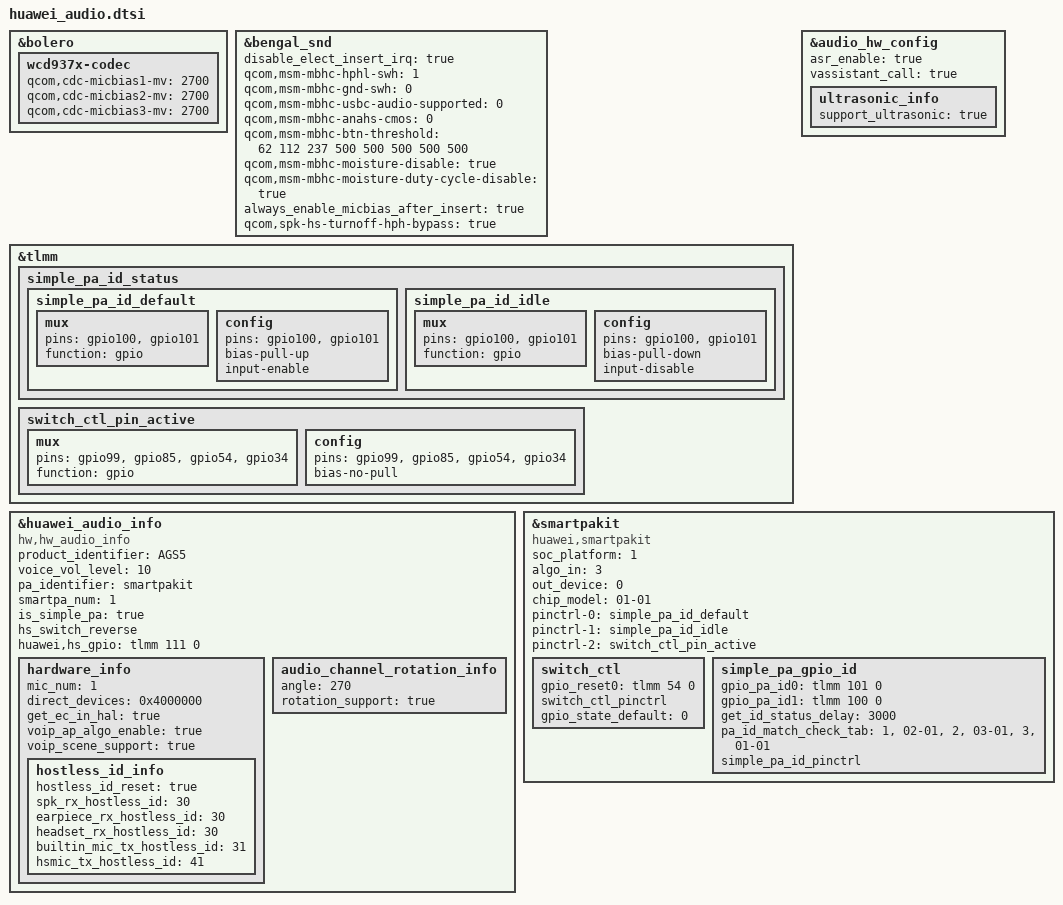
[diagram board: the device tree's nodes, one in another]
&bolero {
	wcd937x-codec {
		qcom,cdc-micbias1-mv = <2700>;
		qcom,cdc-micbias2-mv = <2700>;
		qcom,cdc-micbias3-mv = <2700>;
	};
};

&bengal_snd {
	disable_elect_insert_irq = "true";
	qcom,msm-mbhc-hphl-swh = <1>;
	qcom,msm-mbhc-gnd-swh = <0>;
	qcom,msm-mbhc-usbc-audio-supported = <0>;
	qcom,msm-mbhc-anahs-cmos = <0>;
	qcom,msm-mbhc-btn-threshold = /bits/ 16 <62 112 237 500 500 500 500 500>;
	qcom,msm-mbhc-moisture-disable = "true";
	qcom,msm-mbhc-moisture-duty-cycle-disable = "true";
	always_enable_micbias_after_insert = "true";
	qcom,spk-hs-turnoff-hph-bypass = "true";
};

&tlmm {
	simple_pa_id_status: simple_pa_id_status {
		simple_pa_id_default: simple_pa_id_default {
			mux {
				pins = "gpio100", "gpio101";
				function = "gpio";
			};

			config {
				pins = "gpio100", "gpio101";
				bias-pull-up;
				input-enable;
			};
		};

		simple_pa_id_idle: simple_pa_id_idle {
			mux {
				pins = "gpio100", "gpio101";
				function = "gpio";
			};

			config {
				pins = "gpio100", "gpio101";
				bias-pull-down;
				input-disable;
			};
		};
	};

	switch_ctl_pin_active: switch_ctl_pin_active {
		mux {
			pins = "gpio99", "gpio85", "gpio54", "gpio34";
			function = "gpio";
		};

		config {
			pins = "gpio99", "gpio85", "gpio54", "gpio34";
			bias-no-pull;
		};
	};
};

&huawei_audio_info {
	compatible = "hw,hw_audio_info";
	product_identifier = "AGS5";
	voice_vol_level = "10";
	pa_identifier = "smartpakit";
	smartpa_num = <1>;
	status = "ok";
	is_simple_pa = "true";
	hs_switch_reverse;
	huawei,hs_gpio = <&tlmm 111 0>;
	hardware_info {
		mic_num = "1";
		direct_devices = "0x4000000";
		get_ec_in_hal = "true";
		voip_ap_algo_enable = "true";
		voip_scene_support = "true";
		status = "ok";
		hostless_id_info {
			hostless_id_reset = "true";
			spk_rx_hostless_id = "30";
			earpiece_rx_hostless_id = "30";
			headset_rx_hostless_id = "30";
			builtin_mic_tx_hostless_id = "31";
			hsmic_tx_hostless_id = "41";
		};
	};

	audio_channel_rotation_info {
		angle="270";
		rotation_support= "true";
	};
};

&audio_hw_config {
	asr_enable = "true";
	vassistant_call = "true";
	ultrasonic_info {
		support_ultrasonic = "true";
	};
};

&smartpakit {
	compatible = "huawei,smartpakit";
	/* 0 hisi, 1 qcom */
	soc_platform = <1>;
	/* algo running on: 0 codec_dsp, 1 soc_dsp, 2 smartpa_dsp, 3 simple pa(not smpartpa), 4 simple pa(with i2c) */
	algo_in = <3>;
	/* algo_in params need match out_device for smartpa.
	 * Now, up to only support eight pa, so out_device = <0 0 0 0 0 0 0 0>;
	 * 1. This array is arranged in the following order:
	 *    <0 1 2 3>
	 *    <pril prir secl secr>
	 * 2. This array element value is 0 or 1:
	 *    smartpa: 0 speaker, 1 receiver
	 *    simple pa: out_device not applicable, only set 0 to indicate pa_num
	 * 3. The length of this array is variable, for example:
	 *    single pa: out_device = <0>;
	 *    two pa: out_device = <0 0>;
	 *    four pa: out_device = <1 1 0 0>;
	 *    eight pa: out_device = <0 0 0 0 0 0 0 0>; */
	out_device = <0>;
	/* param_version: 1 mixed smartpa param support */
	status = "ok";
	/* chip_model:
	 * 01-01 : aw-ovs
	 * 01-02 : aw-chn
	 * 02-01 : fs-ovs
	 * 02-02 : fs-chn
	 * 03-01 : sia-ovs
	 * 03-02 : sia-chn
	 */
	chip_model = "01-01";
	pinctrl-names = "default", "idle", "switch_ctl_active";
	pinctrl-0 = <&simple_pa_id_default>;
	pinctrl-1 = <&simple_pa_id_idle>;
	pinctrl-2 = <&switch_ctl_pin_active>;

	switch_ctl {
		gpio_reset0 = <&tlmm 54 0>;
		switch_ctl_pinctrl;
		gpio_state_default = <0>;
	};

	simple_pa_gpio_id {
		gpio_pa_id0 = <&tlmm 101 0>; /* SIA */
		gpio_pa_id1 = <&tlmm 100 0>; /* FS */
		get_id_status_delay = <3000>;
		pa_id_match_check_tab =
			"1", "02-01",
			"2", "03-01",
			"3", "01-01";
		simple_pa_id_pinctrl;
	};
};

